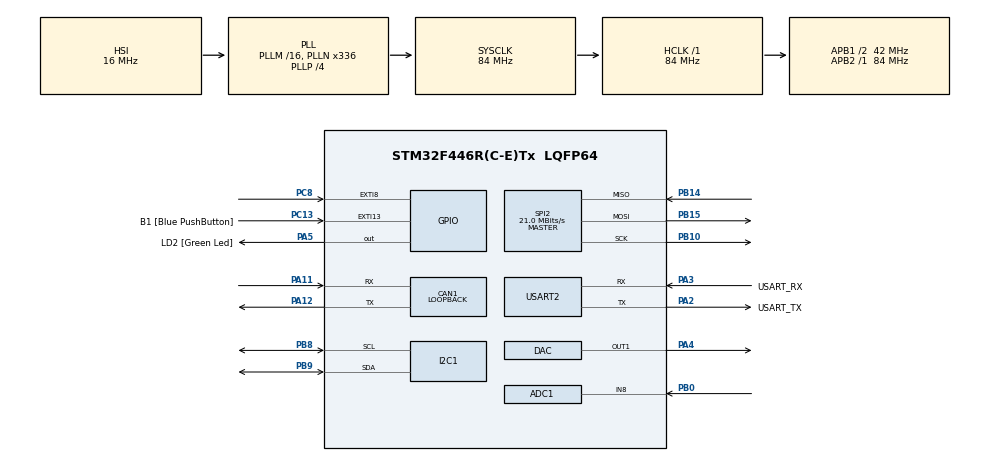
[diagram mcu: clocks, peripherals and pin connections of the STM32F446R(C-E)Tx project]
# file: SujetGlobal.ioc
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ADC1.Channel-0\#ChannelRegularConversion=ADC_CHANNEL_8
ADC1.NbrOfConversionFlag=1
ADC1.Rank-0\#ChannelRegularConversion=1
ADC1.SamplingTime-0\#ChannelRegularConversion=ADC_SAMPLETIME_3CYCLES
ADC1.master=1
CAN1.ABOM=DISABLE
CAN1.AWUM=DISABLE
CAN1.BS1=CAN_BS1_6TQ
CAN1.BS2=CAN_BS2_2TQ
CAN1.CalculateTimeQuantum=380.95238095238096
CAN1.Mode=CAN_MODE_LOOPBACK
CAN1.NART=DISABLE
DAC.DAC_Trigger=DAC_TRIGGER_NONE
Mcu.Family=STM32F4
Mcu.Name=STM32F446R(C-E)Tx
Mcu.Package=LQFP64
NVIC.EXTI9_5_IRQn=true\:0\:0\:false\:false\:true\:true\:true
NVIC.PriorityGroup=NVIC_PRIORITYGROUP_0
NVIC.SPI2_IRQn=true\:0\:0\:false\:false\:true\:true\:true
PA11.GPIO_PuPd=GPIO_PULLUP
PA11.Mode=Master
PA11.Signal=CAN1_RX
PA12.Mode=Master
PA12.Signal=CAN1_TX
PA13.GPIO_Label=TMS
PA13.Mode=Serial_Wire
PA13.Signal=SYS_JTMS-SWDIO
PA14.GPIO_Label=TCK
PA14.Mode=Serial_Wire
PA14.Signal=SYS_JTCK-SWCLK
PA2.GPIO_Label=USART_TX
PA2.Mode=Asynchronous
PA2.Signal=USART2_TX
PA3.GPIO_Label=USART_RX
PA3.Mode=Asynchronous
PA3.Signal=USART2_RX
PA4.Signal=COMP_DAC1_group
PA5.GPIO_Label=LD2 [Green Led]
PA5.Signal=GPIO_Output
PB0.Signal=ADCx_IN8
PB10.Mode=Full_Duplex_Master
PB10.Signal=SPI2_SCK
PB14.Mode=Full_Duplex_Master
PB14.Signal=SPI2_MISO
PB15.Mode=Full_Duplex_Master
PB15.Signal=SPI2_MOSI
PB3.GPIO_Label=SWO
PB3.Signal=SYS_JTDO-SWO
PB8.Mode=I2C
PB8.Signal=I2C1_SCL
PB9.Mode=I2C
PB9.Signal=I2C1_SDA
PC13.GPIO_Label=B1 [Blue PushButton]
PC13.GPIO_ModeDefaultEXTI=GPIO_MODE_IT_FALLING
PC13.Signal=GPXTI13
PC14-OSC32_IN.Mode=LSE-External-Oscillator
PC14-OSC32_IN.Signal=RCC_OSC32_IN
PC15-OSC32_OUT.Mode=LSE-External-Oscillator
PC15-OSC32_OUT.Signal=RCC_OSC32_OUT
PC8.GPIO_ModeDefaultEXTI=GPIO_MODE_IT_FALLING
PC8.Signal=GPXTI8
PH0-OSC_IN.Mode=HSE-External-Oscillator
PH0-OSC_IN.Signal=RCC_OSC_IN
PH1-OSC_OUT.Mode=HSE-External-Oscillator
PH1-OSC_OUT.Signal=RCC_OSC_OUT
ProjectManager.HeapSize=0x200
ProjectManager.StackSize=0x400
ProjectManager.TargetToolchain=STM32CubeIDE
RCC.48MHZClocksFreq_Value=84000000
RCC.AHBFreq_Value=84000000
RCC.APB1CLKDivider=RCC_HCLK_DIV2
RCC.APB1Freq_Value=42000000
RCC.APB1TimFreq_Value=84000000
RCC.APB2Freq_Value=84000000
RCC.APB2TimFreq_Value=84000000
RCC.CortexFreq_Value=84000000
RCC.FLatency-AdvancedSettings=FLASH_LATENCY_2
RCC.HCLKFreq_Value=84000000
RCC.HSE_VALUE=8000000
RCC.HSI_VALUE=16000000
RCC.PLLN=336
RCC.PLLP=RCC_PLLP_DIV4
RCC.SYSCLKFreq_VALUE=84000000
RCC.SYSCLKSource=RCC_SYSCLKSOURCE_PLLCLK
RCC.USBFreq_Value=168000000
RCC.VCOOutputFreq_Value=336000000
SH.ADCx_IN8.0=ADC1_IN8,IN8
SH.COMP_DAC1_group.0=DAC_OUT1,DAC_OUT1
SPI2.CalculateBaudRate=21.0 MBits/s
SPI2.Direction=SPI_DIRECTION_2LINES
SPI2.Mode=SPI_MODE_MASTER
SPI2.VirtualType=VM_MASTER
USART2.VirtualMode=VM_ASYNC
board=NUCLEO-F446RE

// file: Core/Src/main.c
/* USER CODE BEGIN Header */
/**
  ******************************************************************************
  * @file           : main.c
  * @brief          : Main program body
  ******************************************************************************
  * @attention
  *
  * <h2><center>&copy; Copyright (c) 2020 STMicroelectronics.
  * All rights reserved.</center></h2>
  *
  * This software component is licensed by ST under BSD 3-Clause license,
  * the "License"; You may not use this file except in compliance with the
  * License. You may obtain a copy of the License at:
  *                        opensource.org/licenses/BSD-3-Clause
  *
  ******************************************************************************
  */
/* USER CODE END Header */
#include "main.h"

/* USER CODE BEGIN Includes */
#include "System.h"
/* USER CODE END Includes */

ADC_HandleTypeDef hadc1;

CAN_HandleTypeDef hcan1;

DAC_HandleTypeDef hdac;

I2C_HandleTypeDef hi2c1;

SPI_HandleTypeDef hspi2;

UART_HandleTypeDef huart2;

void SystemClock_Config(void);
static void MX_GPIO_Init(void);
static void MX_I2C1_Init(void);
static void MX_USART2_UART_Init(void);
static void MX_ADC1_Init(void);
static void MX_CAN1_Init(void);
static void MX_DAC_Init(void);
static void MX_SPI2_Init(void);

int main(void)
{

  /* MCU Configuration--------------------------------------------------------*/

  /* Reset of all peripherals, Initializes the Flash interface and the Systick. */
  HAL_Init();

  /* Configure the system clock */
  SystemClock_Config();

  /* Initialize all configured peripherals */
  MX_GPIO_Init();
  MX_I2C1_Init();
  MX_USART2_UART_Init();
  MX_ADC1_Init();
  MX_CAN1_Init();
  MX_DAC_Init();
  MX_SPI2_Init();
  /* USER CODE BEGIN 2 */
  System_Init();
  /* USER CODE END 2 */

  /* Infinite loop */
  /* USER CODE BEGIN WHILE */
  while (1)
  {
	  System_Process();
    /* USER CODE END WHILE */

  }
}

void SystemClock_Config(void)
{
  RCC_OscInitTypeDef RCC_OscInitStruct = {0};
  RCC_ClkInitTypeDef RCC_ClkInitStruct = {0};

  /** Configure the main internal regulator output voltage
  */
  __HAL_RCC_PWR_CLK_ENABLE();
  __HAL_PWR_VOLTAGESCALING_CONFIG(PWR_REGULATOR_VOLTAGE_SCALE3);
  /** Initializes the RCC Oscillators according to the specified parameters
  * in the RCC_OscInitTypeDef structure.
  */
  RCC_OscInitStruct.OscillatorType = RCC_OSCILLATORTYPE_HSI;
  RCC_OscInitStruct.HSIState = RCC_HSI_ON;
  RCC_OscInitStruct.HSICalibrationValue = RCC_HSICALIBRATION_DEFAULT;
  RCC_OscInitStruct.PLL.PLLState = RCC_PLL_ON;
  RCC_OscInitStruct.PLL.PLLSource = RCC_PLLSOURCE_HSI;
  RCC_OscInitStruct.PLL.PLLM = 16;
  RCC_OscInitStruct.PLL.PLLN = 336;
  RCC_OscInitStruct.PLL.PLLP = RCC_PLLP_DIV4;
  RCC_OscInitStruct.PLL.PLLQ = 2;
  RCC_OscInitStruct.PLL.PLLR = 2;
  if (HAL_RCC_OscConfig(&RCC_OscInitStruct) != HAL_OK)
  {
    Error_Handler();
  }
  /** Initializes the CPU, AHB and APB buses clocks
  */
  RCC_ClkInitStruct.ClockType = RCC_CLOCKTYPE_HCLK|RCC_CLOCKTYPE_SYSCLK
                              |RCC_CLOCKTYPE_PCLK1|RCC_CLOCKTYPE_PCLK2;
  RCC_ClkInitStruct.SYSCLKSource = RCC_SYSCLKSOURCE_PLLCLK;
  RCC_ClkInitStruct.AHBCLKDivider = RCC_SYSCLK_DIV1;
  RCC_ClkInitStruct.APB1CLKDivider = RCC_HCLK_DIV2;
  RCC_ClkInitStruct.APB2CLKDivider = RCC_HCLK_DIV1;

  if (HAL_RCC_ClockConfig(&RCC_ClkInitStruct, FLASH_LATENCY_2) != HAL_OK)
  {
    Error_Handler();
  }
}

static void MX_ADC1_Init(void)
{

  ADC_ChannelConfTypeDef sConfig = {0};

  /** Configure the global features of the ADC (Clock, Resolution, Data Alignment and number of conversion)
  */
  hadc1.Instance = ADC1;
  hadc1.Init.ClockPrescaler = ADC_CLOCK_SYNC_PCLK_DIV4;
  hadc1.Init.Resolution = ADC_RESOLUTION_12B;
  hadc1.Init.ScanConvMode = DISABLE;
  hadc1.Init.ContinuousConvMode = DISABLE;
  hadc1.Init.DiscontinuousConvMode = DISABLE;
  hadc1.Init.ExternalTrigConvEdge = ADC_EXTERNALTRIGCONVEDGE_NONE;
  hadc1.Init.ExternalTrigConv = ADC_SOFTWARE_START;
  hadc1.Init.DataAlign = ADC_DATAALIGN_RIGHT;
  hadc1.Init.NbrOfConversion = 1;
  hadc1.Init.DMAContinuousRequests = DISABLE;
  hadc1.Init.EOCSelection = ADC_EOC_SINGLE_CONV;
  if (HAL_ADC_Init(&hadc1) != HAL_OK)
  {
    Error_Handler();
  }
  /** Configure for the selected ADC regular channel its corresponding rank in the sequencer and its sample time.
  */
  sConfig.Channel = ADC_CHANNEL_8;
  sConfig.Rank = 1;
  sConfig.SamplingTime = ADC_SAMPLETIME_3CYCLES;
  if (HAL_ADC_ConfigChannel(&hadc1, &sConfig) != HAL_OK)
  {
    Error_Handler();
  }

}

static void MX_CAN1_Init(void)
{

  hcan1.Instance = CAN1;
  hcan1.Init.Prescaler = 16;
  hcan1.Init.Mode = CAN_MODE_LOOPBACK;
  hcan1.Init.SyncJumpWidth = CAN_SJW_1TQ;
  hcan1.Init.TimeSeg1 = CAN_BS1_6TQ;
  hcan1.Init.TimeSeg2 = CAN_BS2_2TQ;
  hcan1.Init.TimeTriggeredMode = DISABLE;
  hcan1.Init.AutoBusOff = DISABLE;
  hcan1.Init.AutoWakeUp = DISABLE;
  hcan1.Init.AutoRetransmission = DISABLE;
  hcan1.Init.ReceiveFifoLocked = DISABLE;
  hcan1.Init.TransmitFifoPriority = DISABLE;
  if (HAL_CAN_Init(&hcan1) != HAL_OK)
  {
    Error_Handler();
  }

}

static void MX_DAC_Init(void)
{

  DAC_ChannelConfTypeDef sConfig = {0};

  /** DAC Initialization
  */
  hdac.Instance = DAC;
  if (HAL_DAC_Init(&hdac) != HAL_OK)
  {
    Error_Handler();
  }
  /** DAC channel OUT1 config
  */
  sConfig.DAC_Trigger = DAC_TRIGGER_NONE;
  sConfig.DAC_OutputBuffer = DAC_OUTPUTBUFFER_ENABLE;
  if (HAL_DAC_ConfigChannel(&hdac, &sConfig, DAC_CHANNEL_1) != HAL_OK)
  {
    Error_Handler();
  }

}

static void MX_I2C1_Init(void)
{

  hi2c1.Instance = I2C1;
  hi2c1.Init.ClockSpeed = 100000;
  hi2c1.Init.DutyCycle = I2C_DUTYCYCLE_2;
  hi2c1.Init.OwnAddress1 = 0;
  hi2c1.Init.AddressingMode = I2C_ADDRESSINGMODE_7BIT;
  hi2c1.Init.DualAddressMode = I2C_DUALADDRESS_DISABLE;
  hi2c1.Init.OwnAddress2 = 0;
  hi2c1.Init.GeneralCallMode = I2C_GENERALCALL_DISABLE;
  hi2c1.Init.NoStretchMode = I2C_NOSTRETCH_DISABLE;
  if (HAL_I2C_Init(&hi2c1) != HAL_OK)
  {
    Error_Handler();
  }

}

static void MX_SPI2_Init(void)
{

  /* SPI2 parameter configuration*/
  hspi2.Instance = SPI2;
  hspi2.Init.Mode = SPI_MODE_MASTER;
  hspi2.Init.Direction = SPI_DIRECTION_2LINES;
  hspi2.Init.DataSize = SPI_DATASIZE_8BIT;
  hspi2.Init.CLKPolarity = SPI_POLARITY_LOW;
  hspi2.Init.CLKPhase = SPI_PHASE_1EDGE;
  hspi2.Init.NSS = SPI_NSS_SOFT;
  hspi2.Init.BaudRatePrescaler = SPI_BAUDRATEPRESCALER_2;
  hspi2.Init.FirstBit = SPI_FIRSTBIT_MSB;
  hspi2.Init.TIMode = SPI_TIMODE_DISABLE;
  hspi2.Init.CRCCalculation = SPI_CRCCALCULATION_DISABLE;
  hspi2.Init.CRCPolynomial = 10;
  if (HAL_SPI_Init(&hspi2) != HAL_OK)
  {
    Error_Handler();
  }

}

static void MX_USART2_UART_Init(void)
{

  huart2.Instance = USART2;
  huart2.Init.BaudRate = 115200;
  huart2.Init.WordLength = UART_WORDLENGTH_8B;
  huart2.Init.StopBits = UART_STOPBITS_1;
  huart2.Init.Parity = UART_PARITY_NONE;
  huart2.Init.Mode = UART_MODE_TX_RX;
  huart2.Init.HwFlowCtl = UART_HWCONTROL_NONE;
  huart2.Init.OverSampling = UART_OVERSAMPLING_16;
  if (HAL_UART_Init(&huart2) != HAL_OK)
  {
    Error_Handler();
  }

}

static void MX_GPIO_Init(void)
{
  GPIO_InitTypeDef GPIO_InitStruct = {0};

  /* GPIO Ports Clock Enable */
  __HAL_RCC_GPIOC_CLK_ENABLE();
  __HAL_RCC_GPIOH_CLK_ENABLE();
  __HAL_RCC_GPIOA_CLK_ENABLE();
  __HAL_RCC_GPIOB_CLK_ENABLE();

  /*Configure GPIO pin Output Level */
  HAL_GPIO_WritePin(LD2_GPIO_Port, LD2_Pin, GPIO_PIN_RESET);

  /*Configure GPIO pins : B1_Pin PC8 */
  GPIO_InitStruct.Pin = B1_Pin|GPIO_PIN_8;
  GPIO_InitStruct.Mode = GPIO_MODE_IT_FALLING;
  GPIO_InitStruct.Pull = GPIO_NOPULL;
  HAL_GPIO_Init(GPIOC, &GPIO_InitStruct);

  /*Configure GPIO pin : LD2_Pin */
  GPIO_InitStruct.Pin = LD2_Pin;
  GPIO_InitStruct.Mode = GPIO_MODE_OUTPUT_PP;
  GPIO_InitStruct.Pull = GPIO_NOPULL;
  GPIO_InitStruct.Speed = GPIO_SPEED_FREQ_LOW;
  HAL_GPIO_Init(LD2_GPIO_Port, &GPIO_InitStruct);

  /* EXTI interrupt init*/
  HAL_NVIC_SetPriority(EXTI9_5_IRQn, 0, 0);
  HAL_NVIC_EnableIRQ(EXTI9_5_IRQn);

}

void Error_Handler(void)
{
}

/************************ (C) COPYRIGHT STMicroelectronics *****END OF FILE****/
